# ATmegaS64M1 register map
Vendor: Atmel; File version: 1.0
CPU: other r0p0, little endian, no MPU, no FPU, 4 interrupt priority bits
Registers are 8-bit, read-write, reset 0x0 unless marked. A register's access mark holds for its fields unless they carry their own. Offsets are from the block's base; [hi:lo] are bit positions; {n}, {i} and the like mark numbered series.

## DAC — Digital-to-Analog Converter
Base 0x00800090
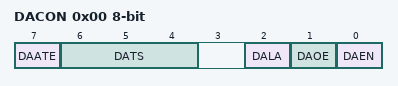
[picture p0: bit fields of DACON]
0x00 DACON — DAC Control Register
  [7] DAATE — DAC Auto Trigger Enable Bit
  [6:4] DATS — DAC Trigger Selection Bits
    0=ANALOG_COMPARATOR_0; 1=ANALOG_COMPARATOR_1; 2=EXTERNAL_INTERRUPT_REQUEST_0; 3=TIMER_COUNTER0_COMPARE_MATCH_A; 4=TIMER_COUNTER0_OVERFLOW; 5=TIMER_COUNTER1_COMPARE_MATCH_B; 6=TIMER_COUNTER1_OVERFLOW; 7=TIMER_COUNTER1_CAPTURE_EVENT
  [2] DALA — DAC Left Adjust
  [1] DAOE — DAC Output Enable
  [0] DAEN — DAC Enable Bit
0x01 DAC 16-bit (reset mask 0xFF) — DAC Data Register (write-only for debugger)
  [15:0] DAC — DAC Data Register Bits

## EEPROM
Base 0x0080003F
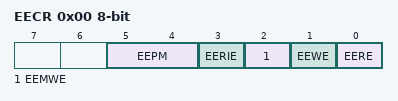
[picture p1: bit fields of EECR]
0x00 EECR — EEPROM Control Register
  [5:4] EEPM — EEPROM Programming mode
    0=ERASE_AND_WRITE_IN_ONE_OPERATION; 1=ERASE_ONLY; 2=WRITE_ONLY
  [3] EERIE — EEPROM Ready Interrupt Enable
  [2] EEMWE — EEPROM Master Write Enable
  [1] EEWE — EEPROM Write Enable
  [0] EERE — EEPROM Read Enable
0x01 EEDR — EEPROM Data Register
0x02 EEAR 16-bit (reset mask 0xFF) — EEPROM Read/Write Access

## EXINT — External Interrupts
Base 0x0080003B
0x00 PCIFR — Pin Change Interrupt Flag Register (write-only for debugger)
  [3:0] PCIF — Pin Change Interrupt Flags
0x01 EIFR — External Interrupt Flag Register (read-only for debugger)
  [3:0] INTF — External Interrupt Flags
0x02 EIMSK — External Interrupt Mask Register
  [3:0] INT — External Interrupt Request 3 Enable
0x2D PCICR — Pin Change Interrupt Control Register (write-only for debugger)
  [3:0] PCIE — Pin Change Interrupt Enables
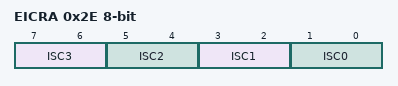
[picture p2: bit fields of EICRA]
0x2E EICRA — External Interrupt Control Register
  [all] fields
    0=LOW_LEVEL_OF_INTX; 1=ANY_LOGICAL_CHANGE_OF_INTX; 2=FALLING_EDGE_OF_INTX; 3=RISING_EDGE_OF_INTX
  [7:6] ISC3 — External Interrupt Sense Control Bit
  [5:4] ISC2 — External Interrupt Sense Control Bit
  [3:2] ISC1 — External Interrupt Sense Control 1 Bits
  [1:0] ISC0 — External Interrupt Sense Control 0 Bits
{0x2F+i} PCMSK{i} (i=0..2) — Pin Change Mask Register {i} (write-only for debugger)
  [7:0] PCINT — Pin Change Enable Masks
0x32 PCMSK3 — Pin Change Mask Register 3 (write-only for debugger)
  [2:0] PCINT — Pin Change Enable Masks

## LINUART — Local Interconnect Network
Base 0x008000C8
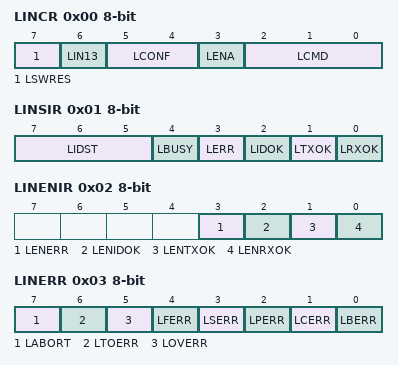
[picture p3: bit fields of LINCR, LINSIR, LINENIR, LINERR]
0x00 LINCR — LIN Control Register
  [7] LSWRES — Software Reset
  [6] LIN13 — LIN Standard
  [5:4] LCONF — LIN Configuration bits
  [3] LENA — LIN or UART Enable
  [2:0] LCMD — LIN Command and Mode bits
0x01 LINSIR — LIN Status and Interrupt Register
  [7:5] LIDST — Identifier Status bits
  [4] LBUSY — Busy Signal
  [3] LERR — Error Interrupt
  [2] LIDOK — Identifier Interrupt
  [1] LTXOK — Transmit Performed Interrupt
  [0] LRXOK — Receive Performed Interrupt
0x02 LINENIR — LIN Enable Interrupt Register
  [3] LENERR — Enable Error Interrupt
  [2] LENIDOK — Enable Identifier Interrupt
  [1] LENTXOK — Enable Transmit Performed Interrupt
  [0] LENRXOK — Enable Receive Performed Interrupt
0x03 LINERR — LIN Error Register (read-only for debugger)
  [7] LABORT — Abort Flag
  [6] LTOERR — Frame Time Out Error Flag
  [5] LOVERR — Overrun Error Flag
  [4] LFERR — Framing Error Flag
  [3] LSERR — Synchronization Error Flag
  [2] LPERR — Parity Error Flag
  [1] LCERR — Checksum Error Flag
  [0] LBERR — Bit Error Flag
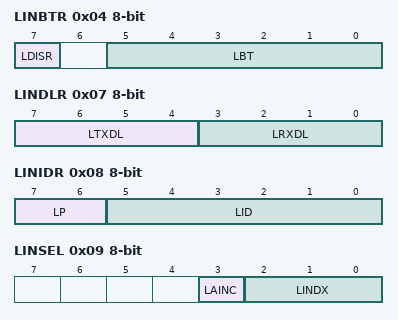
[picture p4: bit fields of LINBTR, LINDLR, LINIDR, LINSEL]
0x04 LINBTR — LIN Bit Timing Register
  [7] LDISR — Disable Bit Timing Resynchronization
  [5:0] LBT — LIN Bit Timing bits
0x05 LINBRR 16-bit (reset mask 0xFF) — LIN Baud Rate Register
  [11:0] LDIV
0x07 LINDLR — LIN Data Length Register
  [7:4] LTXDL — LIN Transmit Data Length bits
  [3:0] LRXDL — LIN Receive Data Length bits
0x08 LINIDR — LIN Identifier Register
  [7:6] LP — Parity bits
  [5:0] LID — Identifier bit 5 or Data Length bits
0x09 LINSEL — LIN Data Buffer Selection Register
  [3] LAINC — Auto Increment of Data Buffer Index (Active Low)
  [2:0] LINDX — FIFO LIN Data Buffer Index bits
0x0A LINDAT — LIN Data Register
  [7:0] LDATA — LIN Data In / Data out
